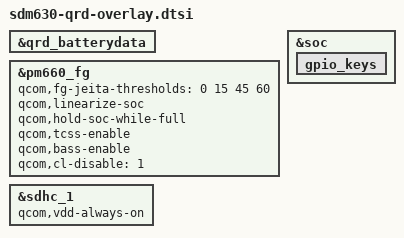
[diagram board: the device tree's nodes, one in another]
/* SPDX-License-Identifier: GPL-2.0 */

&qrd_batterydata {
	/delete-node/ qcom,qrd_msm8998_skuk_3000mah;

	#include "fg-gen3-batterydata-3292665_Huaqin_QL1650cos_5000mAh.dtsi"	
};

&pm660_fg {
	qcom,fg-jeita-thresholds = <0 15 45 60>;
	qcom,linearize-soc;
	qcom,hold-soc-while-full;
	qcom,tcss-enable;
	qcom,bass-enable;
	qcom,cl-disable = <1>;
};

&sdhc_1 {
	qcom,vdd-always-on;
};

&soc {
	gpio_keys {
		/delete-node/ home;
	};
	/delete-node/ hbtp;
};
